VERSION ""

NS_ :

BS_:

BU_: DTR Vehicle

BO_ 3221225472 VECTOR__INDEPENDENT_SIG_MSG: 0 Vector__XXX
 SG_ reserved : 0|1@1+ (1,0) [0|0] "" Vector__XXX
 SG_ SBC_S_H_AKT : 0|1@1+ (1,0) [0|0] "" Vector__XXX
 SG_ FZG_STEHT : 0|1@1+ (1,0) [0|0] "" Vector__XXX
 SG_ VEH_DIR_REVERSE : 0|1@1+ (1,0) [0|0] "" Vector__XXX
 SG_ V_FZG : 0|12@0+ (1,0) [0|0] "" Vector__XXX
 SG_ DTR_SENS_DMODE : 0|2@1+ (1,0) [0|0] "" Vector__XXX
 SG_ DTR_RX_INVALID : 0|1@1+ (1,0) [0|0] "" Vector__XXX
 SG_ DTR_LANE : 0|16@1+ (1,0) [0|0] "" Vector__XXX
 SG_ DTR_CAN_VALID : 0|1@1+ (1,0) [0|0] "" Vector__XXX
 SG_ DTR_AC_LANECFG : 0|2@1+ (1,0) [0|0] "" Vector__XXX
 SG_ SENS_NINIT : 0|1@1+ (1,0) [0|0] "" Vector__XXX
 SG_ SENS_DIRTY : 0|1@1+ (1,0) [0|0] "" Vector__XXX
 SG_ SENS_TXRX_ERR : 0|1@1+ (1,0) [0|0] "" Vector__XXX
 SG_ UB_LOW : 0|1@1+ (1,0) [0|0] "" Vector__XXX
 SG_ OBJ_NVERM : 0|1@1+ (1,0) [0|0] "" Vector__XXX
 SG_ SENS_EXT_ERR : 0|1@1+ (1,0) [0|0] "" Vector__XXX
 SG_ SENS_TEMP_ERR : 0|1@1+ (1,0) [0|0] "" Vector__XXX
 SG_ SEND_DEJUST : 0|1@1+ (1,0) [0|0] "" Vector__XXX
 SG_ SEND_DEF : 0|1@1+ (1,0) [0|0] "" Vector__XXX
 SG_ SENS_SW_KM : 0|8@1+ (1,0) [0|0] "" Vector__XXX
 SG_ SENS_SW_JAHR : 0|8@1+ (1,0) [0|0] "" Vector__XXX
 SG_ SENS_VAR : 0|8@1+ (1,0) [0|0] "" Vector__XXX

BO_ 1624 LWR_MESS1: 8 Vector__XXX

BO_ 273 FBS_111: 8 Vector__XXX

BO_ 1625 LWR_MESS2: 8 Vector__XXX

BO_ 1626 LWR_MESS3: 8 Vector__XXX

BO_ 1648 EDC_MESS1: 8 Vector__XXX

BO_ 1840 SD_RS_LWR: 8 Vector__XXX

BO_ 1597 FS_APPL2: 8 Vector__XXX

BO_ 257 MS_101: 8 Vector__XXX

BO_ 616 MS_268: 8 Vector__XXX
 SG_ PW_F : 40|8@1+ (1,0) [0|0] "" Vector__XXX

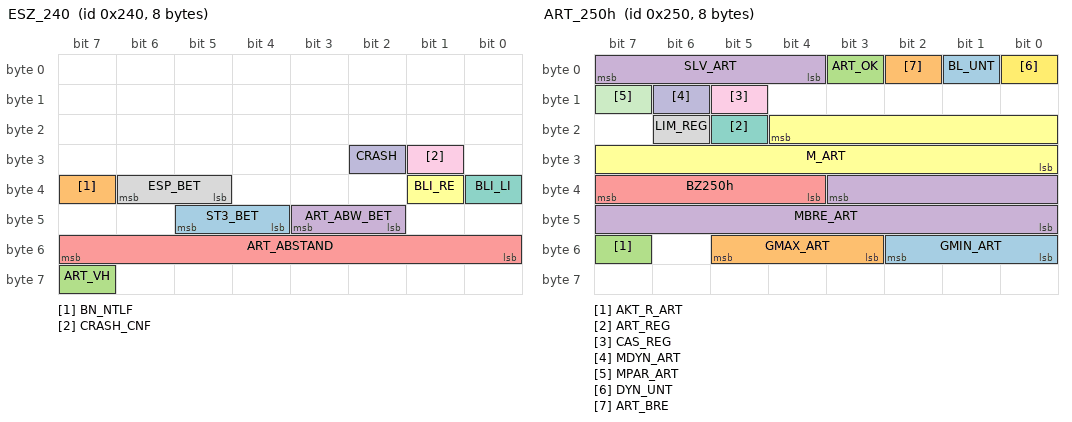
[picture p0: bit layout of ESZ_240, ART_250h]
BO_ 576 ESZ_240: 8 Vector__XXX
 SG_ ST3_BET : 44|2@1+ (1,0) [0|0] "" Vector__XXX
 SG_ BN_NTLF : 39|1@1+ (1,0) [0|0] "" Vector__XXX
 SG_ ART_VH : 63|1@1+ (1,0) [0|0] "" Vector__XXX
 SG_ ART_ABW_BET : 42|2@1+ (1,0) [0|0] "" Vector__XXX
 SG_ ART_ABSTAND : 48|8@1+ (1,0) [0|0] "" Vector__XXX
 SG_ BLI_RE : 33|1@1+ (1,0) [0|0] "" Vector__XXX
 SG_ BLI_LI : 32|1@1+ (1,0) [0|0] "" Vector__XXX
 SG_ ESP_BET : 37|2@1+ (1,0) [0|0] "" Vector__XXX
 SG_ CRASH_CNF : 25|1@1+ (1,0) [0|0] "" Vector__XXX
 SG_ CRASH : 26|1@1+ (1,0) [0|0] "" Vector__XXX

BO_ 592 ART_250h: 8 DTR
 SG_ GMIN_ART : 48|3@1+ (1,0) [0|0] "" Vector__XXX
 SG_ GMAX_ART : 51|3@1+ (1,0) [0|0] "" Vector__XXX
 SG_ AKT_R_ART : 55|1@1+ (1,0) [0|0] "" Vector__XXX
 SG_ MBRE_ART : 35|12@0+ (0.1,0) [0|409.5] "Nm" Vector__XXX
 SG_ BZ250h : 36|4@1+ (1,0) [0|0] "" Vector__XXX
 SG_ M_ART : 20|13@0+ (0.1,0) [0|0] "Nm" Vector__XXX
 SG_ ART_REG : 21|1@1+ (1,0) [0|0] "" Vector__XXX
 SG_ LIM_REG : 22|1@1+ (1,0) [0|0] "" Vector__XXX
 SG_ CAS_REG : 13|1@1+ (1,0) [0|0] "" Vector__XXX
 SG_ MDYN_ART : 14|1@1+ (1,0) [0|0] "" Vector__XXX
 SG_ MPAR_ART : 15|1@1+ (1,0) [0|0] "" Vector__XXX
 SG_ DYN_UNT : 0|1@1+ (1,0) [0|0] "" Vector__XXX
 SG_ BL_UNT : 1|1@1+ (1,0) [0|0] "" Vector__XXX
 SG_ ART_BRE : 2|1@1+ (1,0) [0|0] "" Vector__XXX
 SG_ ART_OK : 3|1@1+ (1,0) [0|0] "" Vector__XXX
 SG_ SLV_ART : 4|4@1+ (1,0) [0|0] "" Vector__XXX

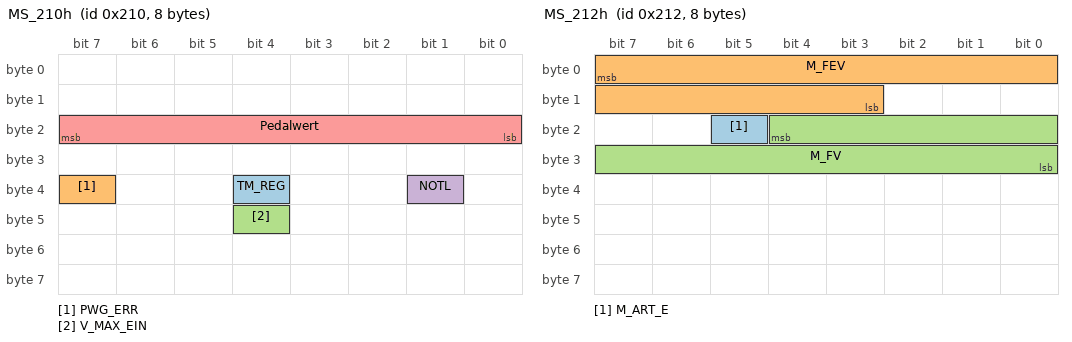
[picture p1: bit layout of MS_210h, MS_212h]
BO_ 528 MS_210h: 8 Vector__XXX
 SG_ TM_REG : 36|1@1+ (1,0) [0|0] "" Vector__XXX
 SG_ PWG_ERR : 39|1@1+ (1,0) [0|0] "" Vector__XXX
 SG_ V_MAX_EIN : 44|1@1+ (1,0) [0|0] "" Vector__XXX
 SG_ NOTL : 33|1@0+ (1,0) [0|0] "" Vector__XXX
 SG_ Pedalwert : 16|8@1+ (0.5,0) [0|0] "%" Vector__XXX

BO_ 530 MS_212h: 8 Vector__XXX
 SG_ M_ART_E : 21|1@1+ (1,0) [0|0] "" Vector__XXX
 SG_ M_FEV : 7|13@0+ (0.1,0) [0|0] "Nm" Vector__XXX
 SG_ M_FV : 20|13@0+ (0.1,0) [0|819.1] "Nm" Vector__XXX

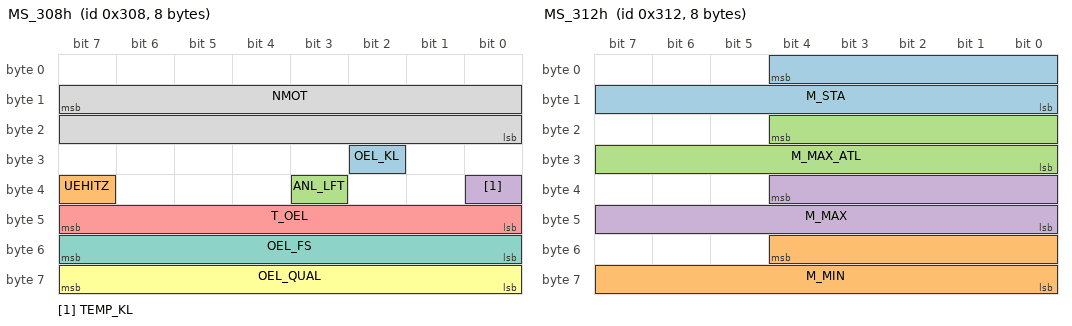
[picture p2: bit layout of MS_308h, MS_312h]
BO_ 776 MS_308h: 8 Vector__XXX
 SG_ OEL_KL : 26|1@1+ (1,0) [0|0] "" Vector__XXX
 SG_ UEHITZ : 39|1@1+ (1,0) [0|0] "" Vector__XXX
 SG_ ANL_LFT : 35|1@1+ (1,0) [0|0] "" Vector__XXX
 SG_ TEMP_KL : 32|1@1+ (1,0) [0|0] "" Vector__XXX
 SG_ T_OEL : 40|8@1+ (0.5,-20) [0|0] "°C" Vector__XXX
 SG_ OEL_QUAL : 56|8@1+ (1,0) [0|0] "" Vector__XXX
 SG_ OEL_FS : 48|8@1+ (1,0) [0|0] "" Vector__XXX
 SG_ NMOT : 15|16@0+ (1,0) [0|0] "rpm" Vector__XXX

BO_ 786 MS_312h: 8 Vector__XXX
 SG_ M_STA : 4|13@0+ (0.1,0) [0|819.1] "Nm" Vector__XXX
 SG_ M_MIN : 52|13@0+ (0.1,0) [0|819.1] "Nm" Vector__XXX
 SG_ M_MAX_ATL : 20|13@0+ (0.1,0) [0|819.1] "Nm" Vector__XXX
 SG_ M_MAX : 36|13@0+ (0.1,0) [0|819.1] "Nm" Vector__XXX

BO_ 1408 AAD_580h: 8 Vector__XXX

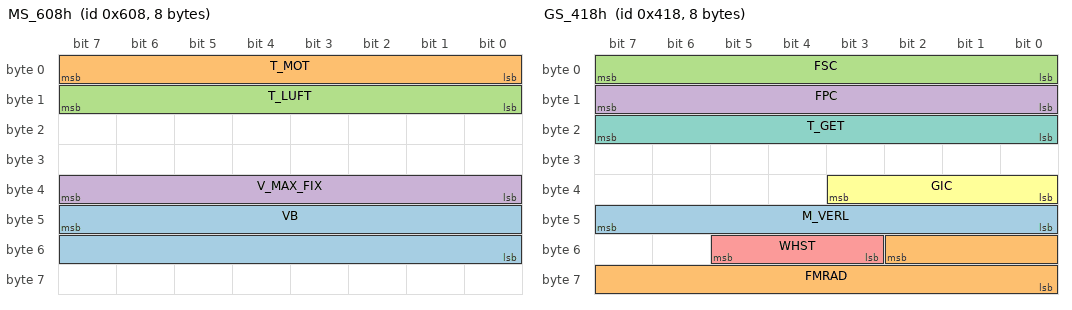
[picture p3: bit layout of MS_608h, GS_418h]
BO_ 1544 MS_608h: 8 Vector__XXX
 SG_ VB : 47|16@0+ (0.01,0) [0|0] "L/100km" Vector__XXX
 SG_ T_MOT : 0|8@1+ (0.5,-20) [0|0] "°C" Vector__XXX
 SG_ T_LUFT : 8|8@1+ (0.5,-20) [0|0] "°C" Vector__XXX
 SG_ V_MAX_FIX : 32|8@1+ (1,0) [0|0] "kph" Vector__XXX

BO_ 824 GS_338h: 8 Vector__XXX

BO_ 1048 GS_418h: 8 Vector__XXX
 SG_ M_VERL : 40|8@1+ (1,0) [0|0] "Nm" Vector__XXX
 SG_ FMRAD : 50|11@0+ (1,0) [0|0] "" Vector__XXX
 SG_ FSC : 0|8@1+ (1,0) [0|0] "" Vector__XXX
 SG_ FPC : 8|8@1+ (1,0) [0|0] "" Vector__XXX
 SG_ WHST : 51|3@1+ (1,0) [0|0] "PRND" Vector__XXX
 SG_ GIC : 32|4@1+ (1,0) [0|0] "Gang" Vector__XXX
 SG_ T_GET : 16|8@1+ (0.5,-20) [0|0] "°C" Vector__XXX

BO_ 560 EWM_230h: 1 Vector__XXX

BO_ 1786 VIN: 8 Vector__XXX

BO_ 584 ZGW_248h: 8 Vector__XXX

BO_ 1038 KLA_40Eh: 8 Vector__XXX

BO_ 1791 CONFIG_6FFh: 8 Vehicle

BO_ 1032 KOMBI_408h: 8 Vector__XXX
 SG_ WRC : 56|3@1+ (1,0) [0|0] "" Vector__XXX
 SG_ ZH_FREIG : 60|1@1+ (1,0) [0|0] "" Vector__XXX
 SG_ SGT_VH : 61|1@1+ (1,0) [0|0] "" Vector__XXX
 SG_ V_DSPL_AKT : 62|1@1+ (1,0) [0|0] "" Vector__XXX
 SG_ WRC3 : 63|1@1+ (1,0) [0|0] "" Vector__XXX
 SG_ KM16 : 47|16@0+ (1,0) [0|0] "" Vector__XXX
 SG_ MAZ : 32|8@1+ (1,0) [0|0] "min" Vector__XXX
 SG_ KL_58D : 24|8@1+ (1,0) [0|0] "" Vector__XXX
 SG_ T_AUSSEN : 23|8@0+ (0.5,-40) [0|0] "°C" Vector__XXX
 SG_ KL_61E : 8|1@1+ (1,0) [0|0] "" Vector__XXX
 SG_ TFSM : 9|1@1+ (1,0) [0|0] "" Vector__XXX
 SG_ VGL_KL_DEF : 10|1@1+ (1,0) [0|0] "" Vector__XXX
 SG_ KLA_VH : 11|1@1+ (1,0) [0|0] "" Vector__XXX
 SG_ V_MPH : 12|1@1+ (1,0) [0|0] "" Vector__XXX
 SG_ TACHO_SYM : 13|1@1+ (1,0) [0|0] "" Vector__XXX
 SG_ V_DSPL_AUS : 14|1@1+ (1,0) [0|0] "" Vector__XXX
 SG_ TF_AUF : 15|1@1+ (1,0) [0|0] "" Vector__XXX
 SG_ TANK_FS : 0|8@1+ (1,0) [0|0] "L" Vector__XXX

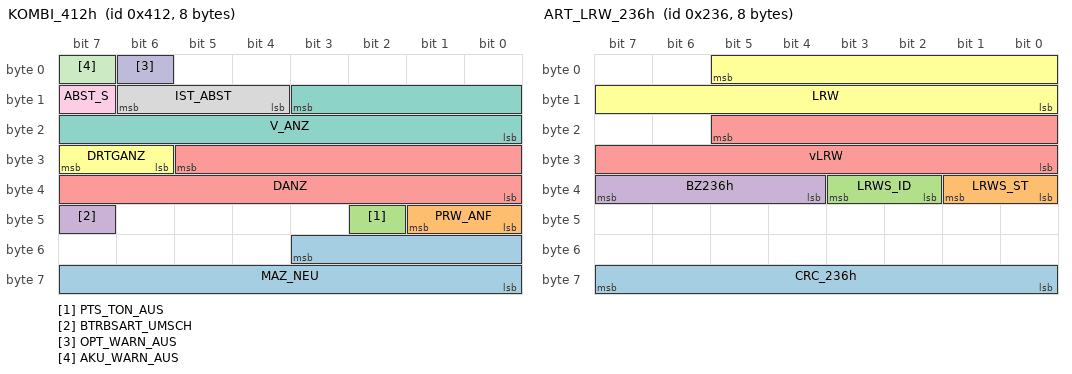
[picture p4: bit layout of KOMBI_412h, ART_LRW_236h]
BO_ 1042 KOMBI_412h: 8 Vector__XXX
 SG_ MAZ_NEU : 51|12@0+ (1,0) [0|0] "min" Vector__XXX
 SG_ PRW_ANF : 40|2@1+ (1,0) [0|0] "" Vector__XXX
 SG_ PTS_TON_AUS : 42|1@1+ (1,0) [0|0] "" Vector__XXX
 SG_ BTRBSART_UMSCH : 47|1@1+ (1,0) [0|0] "" Vector__XXX
 SG_ DANZ : 29|14@0+ (1,0) [0|0] "RPM" Vector__XXX
 SG_ DRTGANZ : 30|2@1+ (1,0) [0|0] "" Vector__XXX
 SG_ V_ANZ : 11|12@0+ (0.1,0) [0|0] "kph" Vector__XXX
 SG_ IST_ABST : 12|3@1+ (1,0) [0|0] "" Vector__XXX
 SG_ ABST_S : 15|1@1+ (1,0) [0|0] "" Vector__XXX
 SG_ OPT_WARN_AUS : 6|1@1+ (1,0) [0|0] "" Vector__XXX
 SG_ AKU_WARN_AUS : 7|1@1+ (1,0) [0|0] "" Vector__XXX

BO_ 566 ART_LRW_236h: 8 Vehicle
 SG_ CRC_236h : 56|8@1+ (1,0) [0|0] "" Vector__XXX
 SG_ LRWS_ST : 32|2@1+ (1,0) [0|0] "" Vector__XXX
 SG_ LRWS_ID : 34|2@1+ (1,0) [0|0] "" Vector__XXX
 SG_ BZ236h : 36|4@1+ (1,0) [0|0] "" Vector__XXX
 SG_ vLRW : 21|14@0+ (0.5,-2048) [0|0] "deg/s²" Vector__XXX
 SG_ LRW : 5|14@0+ (0.5,-2048) [0|0] "deg" Vector__XXX

BO_ 832 FS_340h: 8 Vector__XXX

BO_ 1328 LWR_530h: 2 Vector__XXX

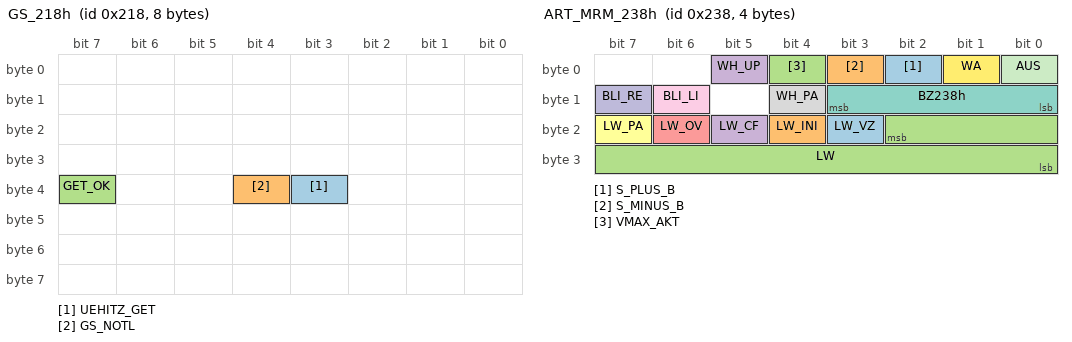
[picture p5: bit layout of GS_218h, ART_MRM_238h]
BO_ 536 GS_218h: 8 Vector__XXX
 SG_ UEHITZ_GET : 35|1@1+ (1,0) [0|0] "" Vector__XXX
 SG_ GS_NOTL : 36|1@1+ (1,0) [0|0] "" Vector__XXX
 SG_ GET_OK : 39|1@1+ (1,0) [0|0] "" Vector__XXX

BO_ 568 ART_MRM_238h: 4 Vehicle
 SG_ LW_VZ : 19|1@1+ (1,0) [0|0] "" Vector__XXX
 SG_ LW_INI : 20|1@1+ (1,0) [0|0] "" Vector__XXX
 SG_ LW : 18|11@0+ (0.5,0) [0|0] "deg" Vector__XXX
 SG_ LW_CF : 21|1@1+ (1,0) [0|0] "" Vector__XXX
 SG_ LW_OV : 22|1@1+ (1,0) [0|0] "" Vector__XXX
 SG_ LW_PA : 23|1@1+ (1,0) [0|0] "" Vector__XXX
 SG_ BZ238h : 8|4@1+ (1,0) [0|0] "" Vector__XXX
 SG_ WH_PA : 12|1@1+ (1,0) [0|0] "" Vector__XXX
 SG_ BLI_LI : 14|1@1+ (1,0) [0|0] "" Vector__XXX
 SG_ BLI_RE : 15|1@1+ (1,0) [0|0] "" Vector__XXX
 SG_ AUS : 0|1@1+ (1,0) [0|0] "" Vector__XXX
 SG_ WA : 1|1@1+ (1,0) [0|0] "" Vector__XXX
 SG_ S_PLUS_B : 2|1@1+ (1,0) [0|0] "" Vector__XXX
 SG_ S_MINUS_B : 3|1@1+ (1,0) [0|0] "" Vector__XXX
 SG_ VMAX_AKT : 4|1@1+ (1,0) [0|0] "" Vector__XXX
 SG_ WH_UP : 5|1@1+ (1,0) [0|0] "" Vector__XXX

BO_ 1040 KLA_410h: 8 Vector__XXX

BO_ 1628 BS_65Ch: 8 Vector__XXX

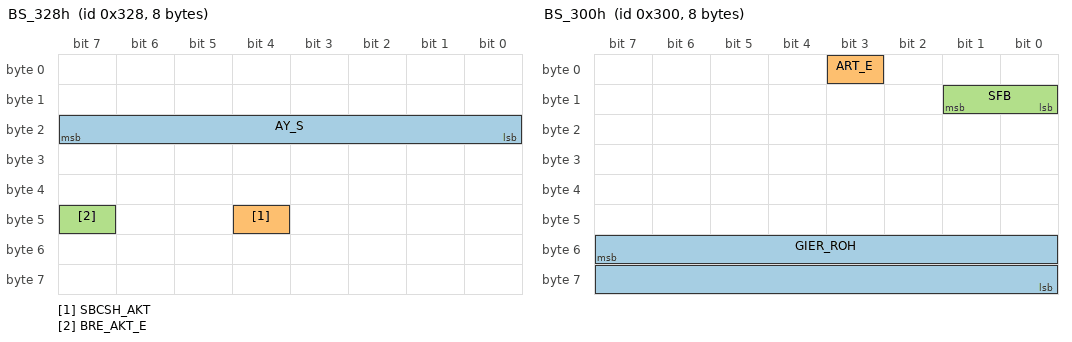
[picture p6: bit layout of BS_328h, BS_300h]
BO_ 808 BS_328h: 8 Vector__XXX
 SG_ AY_S : 16|8@1+ (0.1,0) [0|0] "m/s²" Vector__XXX
 SG_ SBCSH_AKT : 44|1@1+ (1,0) [0|0] "" Vector__XXX
 SG_ BRE_AKT_E : 47|1@1+ (1,0) [0|0] "" Vector__XXX

BO_ 768 BS_300h: 8 Vector__XXX
 SG_ GIER_ROH : 55|16@0+ (0.0001,-3.2768) [-3.2768|3.2767] "rad/s" Vector__XXX
 SG_ ART_E : 3|1@1+ (1,0) [0|0] "" Vector__XXX
 SG_ SFB : 8|2@1+ (1,0) [0|0] "" Vector__XXX

BO_ 600 ART_258h: 8 DTR
 SG_ ASSIST_ANZ_V2 : 56|5@1+ (1,0) [0|0] "" Vector__XXX
 SG_ CAS_ERR_ANZ_V2 : 61|3@1+ (1,0) [0|0] "" Vector__XXX
 SG_ ASSIST_FKT_AKT : 48|2@1+ (1,0) [0|0] "" Vector__XXX
 SG_ AAS_LED_BL : 50|1@1+ (1,0) [0|0] "" Vector__XXX
 SG_ OBJ_AGB : 51|1@1+ (1,0) [0|0] "" Vector__XXX
 SG_ ART_ABW_AKT : 52|1@1+ (1,0) [0|0] "" Vector__XXX
 SG_ ART_REAKT : 53|1@1+ (1,0) [0|0] "" Vector__XXX
 SG_ ART_UEBERSP : 54|1@1+ (1,0) [0|0] "" Vector__XXX
 SG_ ART_DSPL_NEU : 55|1@1+ (1,0) [0|0] "" Vector__XXX
 SG_ V_ZIEL : 40|8@1+ (1,0) [0|0] "kmh" Vector__XXX
 SG_ TM_EIN_ART : 32|1@1+ (1,0) [0|0] "" Vector__XXX
 SG_ ART_DSPL_BL : 33|1@1+ (1,0) [0|0] "" Vector__XXX
 SG_ ART_SEG_EIN : 34|1@1+ (1,0) [0|0] "" Vector__XXX
 SG_ OBJ_ERK : 35|1@1+ (1,0) [0|0] "" Vector__XXX
 SG_ ART_EIN : 36|1@1+ (1,0) [0|0] "" Vector__XXX
 SG_ ART_DSPL_LIM : 37|1@1+ (1,0) [0|0] "" Vector__XXX
 SG_ ART_VFBR : 38|1@1+ (1,0) [0|0] "" Vector__XXX
 SG_ ART_DSPL_PGB : 39|1@1+ (1,0) [0|0] "" Vector__XXX
 SG_ SOLL_ABST : 24|8@1+ (1,0) [0|0] "m" Vector__XXX
 SG_ ABST_R_OBJ : 16|8@1+ (1,0) [0|0] "m" Vector__XXX
 SG_ V_ART : 8|8@1+ (1,0) [0|0] "kmh" Vector__XXX
 SG_ ART_ERROR : 0|4@1+ (1,0) [0|0] "" Vector__XXX
 SG_ ART_INFO : 4|1@1+ (1,0) [0|0] "" Vector__XXX
 SG_ ART_WT : 5|1@1+ (1,0) [0|0] "" Vector__XXX
 SG_ S_OBJ : 6|1@1+ (1,0) [0|0] "" Vector__XXX
 SG_ ART_DSPL_EIN : 7|1@1+ (1,0) [0|0] "" Vector__XXX

BO_ 520 BS_208h: 8 Vector__XXX

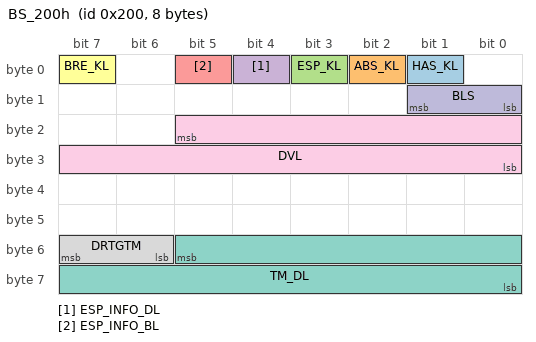
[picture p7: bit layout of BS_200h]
BO_ 512 BS_200h: 8 Vector__XXX
 SG_ HAS_KL : 1|1@1+ (1,0) [0|0] "" Vector__XXX
 SG_ ABS_KL : 2|1@1+ (1,0) [0|0] "" Vector__XXX
 SG_ ESP_KL : 3|1@1+ (1,0) [0|0] "" Vector__XXX
 SG_ ESP_INFO_DL : 4|1@1+ (1,0) [0|0] "" Vector__XXX
 SG_ ESP_INFO_BL : 5|1@1+ (1,0) [0|0] "" Vector__XXX
 SG_ BRE_KL : 7|1@1+ (1,0) [0|0] "" Vector__XXX
 SG_ TM_DL : 53|14@0+ (1,0) [0|0] "rpm" Vector__XXX
 SG_ DRTGTM : 54|2@1+ (1,0) [0|0] "" Vector__XXX
 SG_ DVL : 21|14@0+ (1,0) [0|0] "?" Vector__XXX
 SG_ BLS : 8|2@1+ (1,0) [0|0] "" Vector__XXX

CM_ BU_ DTR "Abstands Regel Tempomat
Distronic Control Modul";
CM_ BO_ 3221225472 "This is a message for not used signals, created by Vector CANdb++ DBC OLE DB Provider.";
CM_ SG_ 3221225472 SBC_S_H_AKT "SBC-S/H aktiv, ASG darf nicht nach N schalten";
CM_ SG_ 3221225472 FZG_STEHT "Fahrzeug Stillstand erkannt";
CM_ SG_ 3221225472 VEH_DIR_REVERSE "Vehicle direction reverse";
CM_ SG_ 3221225472 V_FZG "Eigengeschwindigkeit Fahrzeug";
CM_ SG_ 3221225472 DTR_SENS_DMODE "DTR Sensor Diagnosemode";
CM_ SG_ 3221225472 DTR_RX_INVALID "RX invalid (Timeout,Parity,MC)";
CM_ SG_ 3221225472 DTR_LANE "DTR -Spur";
CM_ SG_ 3221225472 DTR_CAN_VALID "DTR CAN valid  (Valid CAN-Data)";
CM_ SG_ 3221225472 DTR_AC_LANECFG "Active lane configuration numeric 
Left, Center, Right?";
CM_ SG_ 3221225472 SENS_NINIT "Sensor nicht initialisiert";
CM_ SG_ 3221225472 SENS_DIRTY "Sensor / Sensorabdeckung verschmutzt";
CM_ SG_ 3221225472 SENS_TXRX_ERR "Sensor hat Sende- / Empfangsprobleme";
CM_ SG_ 3221225472 UB_LOW "Unterspannung erkannt";
CM_ SG_ 3221225472 OBJ_NVERM "Objekt nicht vermessen";
CM_ SG_ 3221225472 SENS_EXT_ERR "Sensor extern gestört";
CM_ SG_ 3221225472 SENS_TEMP_ERR "Sensorabschaltung wegen Temperatur";
CM_ SG_ 3221225472 SEND_DEJUST "SENS_DEJUST";
CM_ SG_ 3221225472 SEND_DEF "Sensor defekt";
CM_ SG_ 3221225472 SENS_SW_KM "Sensor Software Kalenderwoche";
CM_ SG_ 3221225472 SENS_SW_JAHR "Sensor Software Jahr";
CM_ SG_ 3221225472 SENS_VAR "Sensor Variante";
CM_ SG_ 616 PW_F "Pedalwert Fahrer (nur 169)";
CM_ SG_ 576 ST3_BET "LF/ABC 3-stufiger Schalter betätigt";
CM_ SG_ 576 BN_NTLF "Bordnetz-Notlauf: Prio1- und Prio2-Verbraucher aus, Zweite Batterie stützt";
CM_ SG_ 576 ART_VH "ART Vorhanden available";
CM_ SG_ 576 ART_ABW_BET "ART-distance warning actuated on / off
0 nijts
2 switch";
CM_ SG_ 576 ART_ABSTAND "Abstandsfaktor
0-200
default 100";
CM_ SG_ 576 BLI_RE "Richtungsblinken rechts";
CM_ SG_ 576 BLI_LI "Richtungsblinken links";
CM_ SG_ 576 ESP_BET "BET - Betätigt
ESP operated on / off
1 betätigung";
CM_ SG_ 576 CRASH_CNF "CRASH Confirmbit";
CM_ SG_ 576 CRASH "CRASH";
CM_ BO_ 592 "Regel Anforderungen";
CM_ SG_ 592 GMIN_ART "Sollgang, untere Grenze";
CM_ SG_ 592 GMAX_ART "Sollgang, obere Grenze";
CM_ SG_ 592 AKT_R_ART "ART-Wunsch: Aktive Rückschaltung";
CM_ SG_ 592 MBRE_ART "Bremsmoment (0000h: Passivwert)";
CM_ SG_ 592 BZ250h "Botschaftszähler";
CM_ SG_ 592 M_ART "Geford. Motormoment";
CM_ SG_ 592 ART_REG "ART regelt";
CM_ SG_ 592 LIM_REG "Limiter regelt";
CM_ SG_ 592 CAS_REG "Cityassistent regelt";
CM_ SG_ 592 MDYN_ART "Motormomentenanforderung Dynamisch";
CM_ SG_ 592 MPAR_ART "Motormomentenanforderung Parity (gerade Parität)";
CM_ SG_ 592 DYN_UNT "Unterdrückung dynamische Vollastrückschaltung";
CM_ SG_ 592 BL_UNT "Bremslichtunterdrückung";
CM_ SG_ 592 ART_BRE "ART bremst";
CM_ SG_ 592 ART_OK "ART in Ordnung";
CM_ SG_ 592 SLV_ART "Schaltlinienverschiebung ART";
CM_ BO_ 528 "Motor";
CM_ SG_ 528 TM_REG "Tempomat regelt";
CM_ SG_ 528 PWG_ERR "Fehler Pedalwertgeber";
CM_ SG_ 528 V_MAX_EIN "Geschwindigkeitsbegrenzung eingeschaltet";
CM_ SG_ 528 NOTL "Notlaufbetrieb";
CM_ SG_ 528 Pedalwert "Pedalwert
max 92";
CM_ BO_ 530 "Motor";
CM_ SG_ 530 M_ART_E "Enable Momentenanforderung ART";
CM_ SG_ 530 M_FEV "Ersatzvorgabemoment Fahrer";
CM_ SG_ 530 M_FV "Vorgabemoment Fahrer";
CM_ BO_ 776 "Motor infos fürs Dash";
CM_ SG_ 776 OEL_KL "Ölstand/Öldruck Kontrollampe";
CM_ SG_ 776 UEHITZ "Motoröltemperatur zu hoch (Überhitzung)";
CM_ SG_ 776 ANL_LFT "Anlasser läuft";
CM_ SG_ 776 TEMP_KL "Kühlwassertemperatur zu hoch";
CM_ SG_ 776 T_OEL "Öltemperatur";
CM_ SG_ 776 OEL_QUAL "Ölqualität";
CM_ SG_ 776 OEL_FS "Ölstand";
CM_ SG_ 776 NMOT "Motordrehzahl";
CM_ BO_ 786 "Motor";
CM_ SG_ 786 M_STA "Motormoment statisch";
CM_ SG_ 786 M_MIN "Motormoment minimal";
CM_ SG_ 786 M_MAX_ATL "Motormoment maximal incl. dyn. Turboladeranteil";
CM_ SG_ 786 M_MAX "Motormoment maximal";
CM_ BO_ 1408 "Fahrer";
CM_ BO_ 1544 "Fahrzeuginfos";
CM_ SG_ 1544 VB "Verbrauch";
CM_ SG_ 1544 T_MOT "Motorkühlmitteltemperatur";
CM_ SG_ 1544 T_LUFT "Ansauglufttemperatur";
CM_ SG_ 1544 V_MAX_FIX "Feste Höchstgeschwindigkeit";
CM_ BO_ 824 "Getriebe";
CM_ BO_ 1048 "Getriebe";
CM_ SG_ 1048 M_VERL "Verlustmoment (FFh bei KSG)";
CM_ SG_ 1048 FMRAD "Faktor Radmoment (7FFh bei KSG)";
CM_ SG_ 1048 FSC "Farstufe";
CM_ SG_ 1048 FPC "Fahrprogramm";
CM_ SG_ 1048 WHST "Getriebewählhebelstellung (NAG, KSG, CVT)
7 unknow
0 Park
1 Reverse
2 N
4 D
";
CM_ SG_ 1048 GIC "Ist Gang
12 P
0 N";
CM_ SG_ 1048 T_GET "Getriebeöltemperatur";
CM_ BO_ 560 "Getrieb";
CM_ BO_ 1786 "VIN";
CM_ BO_ 584 "Informationen ";
CM_ BO_ 1038 "Klima 

Anforderung Heizleistung";
CM_ BO_ 1791 "Vehicle Config";
CM_ BO_ 1032 "Kombi Daten";
CM_ SG_ 1032 WRC "Winterreifen-Höchstgeschwindigkeit mit 4 Bit";
CM_ SG_ 1032 ZH_FREIG "Freigabe Zuheizer";
CM_ SG_ 1032 SGT_VH "Segment-Tacho vorhanden";
CM_ SG_ 1032 V_DSPL_AKT "Geschw.begrenzer-/Tempomat-Anzeige aktiv";
CM_ SG_ 1032 WRC3 "Winterreifen-Höchstgeschwindigkeit Bit 3";
CM_ SG_ 1032 KM16 "Kilometerstand";
CM_ SG_ 1032 MAZ "Motorabstellzeit (wird ab Kl.15 gesendet) oder Anstellzeit?";
CM_ SG_ 1032 KL_58D "Klemme 58 gedimmt
Regelbare Instrumentenbeleuchtung";
CM_ SG_ 1032 T_AUSSEN "Außenlufttemperatur Rohwert";
CM_ SG_ 1032 KL_61E "Klemme 61 entkoppelt  Alternator is running";
CM_ SG_ 1032 TFSM "Tankfüllstandsminimum";
CM_ SG_ 1032 VGL_KL_DEF "Vorglüh Kontrollampe defekt";
CM_ SG_ 1032 KLA_VH "Klimaanlage vorhanden";
CM_ SG_ 1032 V_MPH "mph statt km/h (variable Geschwindigkeitsbegr.)";
CM_ SG_ 1032 TACHO_SYM "Tachoeichung";
CM_ SG_ 1032 V_DSPL_AUS "Geschw.begrenzer-/Tempomat-Anzeige nicht möglich";
CM_ SG_ 1032 TF_AUF "Fahrertür auf";
CM_ SG_ 1032 TANK_FS "Tankfüllstand";
CM_ BO_ 1042 "Kombi Daten";
CM_ SG_ 1042 MAZ_NEU "Motorabstellzeit oder Motorlaufzeit?";
CM_ SG_ 1042 PRW_ANF "Anforderung Plattrollwarner";
CM_ SG_ 1042 PTS_TON_AUS "Parktronic Warnton ist ausgeschaltet";
CM_ SG_ 1042 BTRBSART_UMSCH "Betriebsart Umschaltung";
CM_ SG_ 1042 DANZ "Raddrehzahl errechnet aus V_ANZ";
CM_ SG_ 1042 DRTGANZ "Raddrehrichtung zu V_ANZ";
CM_ SG_ 1042 V_ANZ "Angezeigte Geschwindigkeit";
CM_ SG_ 1042 IST_ABST "Eingestellter Abstand";
CM_ SG_ 1042 ABST_S "Abstandseinheit";
CM_ SG_ 1042 OPT_WARN_AUS "Optische Warnung aus";
CM_ SG_ 1042 AKU_WARN_AUS "Akustische Warnung aus";
CM_ BO_ 566 "Lenk Rad Winkel";
CM_ SG_ 566 CRC_236h "CRC-Checksumme Byte 1 - 7 nach SAE J1850";
CM_ SG_ 566 LRWS_ST "Status Lenkradwinkelsensor";
CM_ SG_ 566 LRWS_ID "Identifikation Lenkradwinkelsensor";
CM_ SG_ 566 BZ236h "Botschaftszähler";
CM_ SG_ 566 vLRW "Lenkradwinkelgeschwindigkeit";
CM_ SG_ 566 LRW "Lenkradwinkel
+ R
- L
";
CM_ BO_ 832 "Fahrzeug Niveau Meldungen";
CM_ BO_ 1328 "LeuchtWeitenRegulierung Meldungen";
CM_ BO_ 536 "Getriebe";
CM_ SG_ 536 UEHITZ_GET "Overtemperature gear";
CM_ SG_ 536 GS_NOTL "GS in emergency operation";
CM_ SG_ 536 GET_OK "transmission ok";
CM_ BO_ 568 "ART_ABSTAND - Abstandsfaktor
Bedienelemente";
CM_ SG_ 568 LW_VZ "Lenkwinkel-Vorzeichen";
CM_ SG_ 568 LW_INI "Lenkwinkelsensor: nicht initialisiert";
CM_ SG_ 568 LW "Lenkwinkel";
CM_ SG_ 568 LW_CF "Lenkwinkelsensor: Codefehler";
CM_ SG_ 568 LW_OV "Lenkwinkelsensor: Überlauf";
CM_ SG_ 568 LW_PA "Lenkwinkel Parität (gerade Parität)";
CM_ SG_ 568 BZ238h "Botschaftszähler";
CM_ SG_ 568 WH_PA "Tempomatwählhebel Parity (gerade Parität) on changes";
CM_ SG_ 568 BLI_LI "Richtungsblinken links";
CM_ SG_ 568 BLI_RE "Richtungsblinken rechts";
CM_ SG_ 568 AUS "Tempomatwählhebel: Ausschalten";
CM_ SG_ 568 WA "Tempomatwählhebel: Wiederaufnahme";
CM_ SG_ 568 S_PLUS_B "Tempomatwählhebel: Setzen und Beschleunigen Stufe0";
CM_ SG_ 568 S_MINUS_B "Tempomatwählhebel: Setzen und verzögern Stufe0";
CM_ SG_ 568 VMAX_AKT "Bedienung variable Geschwindigkeitsbegrenzung";
CM_ SG_ 568 WH_UP "Tempomatwählhebel unplausibel";
CM_ BO_ 1040 "Klima Automatik";
CM_ SG_ 808 AY_S "lat accelration at center of gravity (+ = Left)";
CM_ SG_ 808 SBCSH_AKT "Stauassistent/Hillholder aktiv (nur 211/230)";
CM_ SG_ 808 BRE_AKT_E "Bremsdruckregelung möglich";
CM_ SG_ 768 GIER_ROH "Rohsignal Gierrate ohne Abgleich/Filterung (+ = links) 
RAD / sec";
CM_ SG_ 768 ART_E "Enable ART";
CM_ SG_ 768 SFB "Fahrer bremst";
CM_ SG_ 600 ASSIST_ANZ_V2 "Assistenzsystem Anzeigeanforderung";
CM_ SG_ 600 CAS_ERR_ANZ_V2 "CAS Anzeigeanforderung";
CM_ SG_ 600 ASSIST_FKT_AKT "Aktive Funktion";
CM_ SG_ 600 AAS_LED_BL "LED Abstandsassistent blinken";
CM_ SG_ 600 OBJ_AGB "Objekt Angebot Abstandsassistent";
CM_ SG_ 600 ART_ABW_AKT "ART-Abstandswarnung ist eingeschaltet";
CM_ SG_ 600 ART_REAKT "Anzeige der Systemverfügbarkeit nach Systemfehler";
CM_ SG_ 600 ART_UEBERSP "ART wird vom Fahrer überspielt PASSIV?";
CM_ SG_ 600 ART_DSPL_NEU "Mindestanzeigezeit im Display neu triggern";
CM_ SG_ 600 V_ZIEL "Geschwindigkeit erkanntes Zielfahrzeug";
CM_ SG_ 600 TM_EIN_ART "ART-Tempomat eingeschaltet";
CM_ SG_ 600 ART_DSPL_BL "Geschwindigkeitsanzeige blinken";
CM_ SG_ 600 ART_SEG_EIN "ART-Segmentanzeige einschalten";
CM_ SG_ 600 OBJ_ERK "Relevantes Objekt erkannt";
CM_ SG_ 600 ART_EIN "Abstandsregeltempomat eingeschaltet";
CM_ SG_ 600 ART_DSPL_LIM "Anzeige --- am Display wenn man zu langsam oder zu schnell ist";
CM_ SG_ 600 ART_VFBR "Anzeige DTR AUS [0]";
CM_ SG_ 600 ART_DSPL_PGB "Anzeige Winterreifenbegrenzung erreicht";
CM_ SG_ 600 SOLL_ABST "Fahrerwunschabstand";
CM_ SG_ 600 ABST_R_OBJ "Abstand relevantes Objekt";
CM_ SG_ 600 V_ART "eingestellte ART-Geschwindigkeit";
CM_ SG_ 600 ART_ERROR "ART Fehlercode
1 - 0001 - Distronic momntan nicht vergügbar! Siehe Betriebsanleitung.
2 - 0010 - Distronic Werkstatt aufsuchen!
4 - 0100 - Externe Störung! Neu aktivieren!
8 - 1000 - nothing
";
CM_ SG_ 600 ART_INFO "ART Infolampe (Rotes Dreieck)";
CM_ SG_ 600 ART_WT "ART Warnton BEEEP";
CM_ SG_ 600 S_OBJ "Erkennung stehendes Objekt";
CM_ SG_ 600 ART_DSPL_EIN "Display auf ART-Anzeige schalten";
CM_ SG_ 512 HAS_KL "Handbremse gezogen Kontrollampe
";
CM_ SG_ 512 ABS_KL "ABS defekt Kontrollampe";
CM_ SG_ 512 ESP_KL "ESP defekt Kontrolllampe";
CM_ SG_ 512 ESP_INFO_DL "ESP Infolampe Dauerlicht";
CM_ SG_ 512 ESP_INFO_BL "ESP Infolampe Blinklicht";
CM_ SG_ 512 BRE_KL "Bremse defekt Kontrollampe
";
CM_ SG_ 512 TM_DL "Wheel left for cruise control";
CM_ SG_ 512 DRTGTM "Rotation direction left wheel for cruise control
0 - stop
1 - D
2 - R ?";
CM_ SG_ 512 DVL "Front left wheel speed";
CM_ SG_ 512 BLS "Bremslichtschalter";
BA_DEF_ SG_  "GenSigSendType" ENUM  "Cyclic","OnWrite","OnWriteWithRepetition","OnChange","OnChangeWithRepetition","IfActive","IfActiveWithRepetition","NoSigSendType";
BA_DEF_ BO_  "GenMsgSendType" ENUM  "Cyclic","not_used","not_used","not_used","not_used","Cyclic","not_used","IfActive","NoMsgSendType";
BA_DEF_  "DBName" STRING ;
BA_DEF_  "BusType" STRING ;
BA_DEF_DEF_  "GenSigSendType" "Cyclic";
BA_DEF_DEF_  "GenMsgSendType" "NoMsgSendType";
BA_DEF_DEF_  "DBName" "";
BA_DEF_DEF_  "BusType" "CAN";
BA_ "DBName" "CAN_C";
